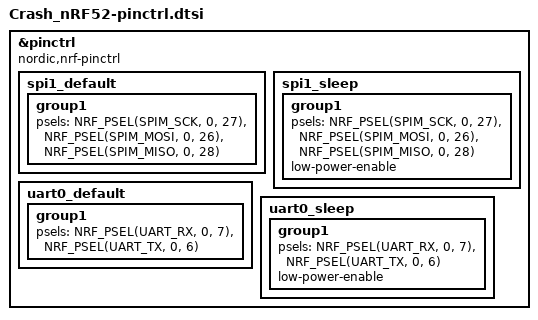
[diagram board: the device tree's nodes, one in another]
&pinctrl {
    compatible = "nordic,nrf-pinctrl";
	spi1_default: spi1_default {
		group1 {
			psels = <NRF_PSEL(SPIM_SCK, 0, 27)>,
					<NRF_PSEL(SPIM_MOSI, 0, 26)>,
					<NRF_PSEL(SPIM_MISO, 0, 28)>;
		};
	};
	spi1_sleep: spi1_sleep {
        group1 {
			psels = <NRF_PSEL(SPIM_SCK, 0, 27)>,
					<NRF_PSEL(SPIM_MOSI, 0, 26)>,
					<NRF_PSEL(SPIM_MISO, 0, 28)>;
			low-power-enable;
		};
	};
	uart0_default: uart0_default {
		group1 {
			psels = <NRF_PSEL(UART_RX, 0, 7)>,
					<NRF_PSEL(UART_TX, 0, 6)>;
		};
	};
	uart0_sleep: uart0_sleep {
		group1 {
			psels = <NRF_PSEL(UART_RX, 0, 7)>,
					<NRF_PSEL(UART_TX, 0, 6)>;
			low-power-enable;
		};
	};

};
